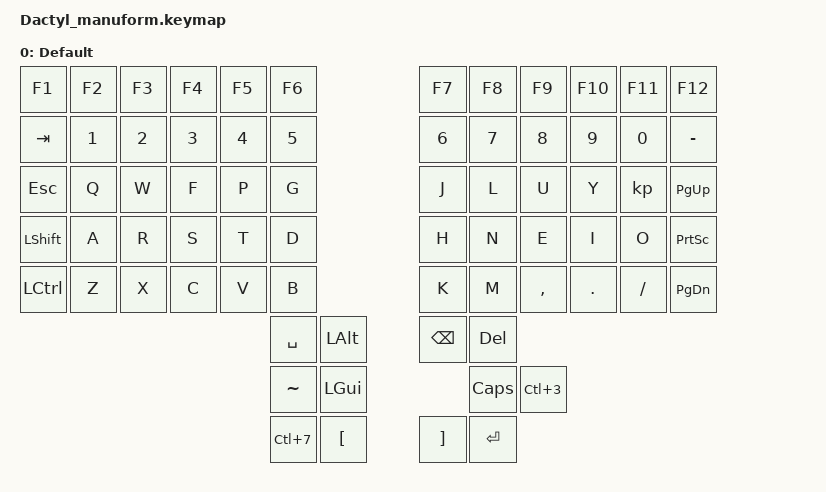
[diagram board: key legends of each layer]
#define DEFAULT 0
//#define LOWER   1
//#define RAISE   2
//#define ADJUST  3

#define HYPER(key) LS(LC(LA(LG(key))))
#define MEH(key)   LS(LC(LA(key)))

&kpkscan0 {
    debounce-press-ms = <30>;
    debounce-release-ms = <30>;
};

/ {
    keymap {
        compatible = "zmk,keymap";

        // Default layer. Modeled after the original Kinesis layout with a few tweaks.
        // Equals above tab = ESC
        // Backslash below minus = Equals
        // Swapped up and down arrows
        default_layer {
            display-name = "Default";
            bindings = <
        &kp F1  &kp F2  &kp F3  &kp F4  &kp F5  &kp F6                  &kp F7 &kp F8 &kp F9      &kp F10  &kp F11    &kp F12
        &kp TAB &kp N1  &kp N2  &kp N3  &kp N4  &kp N5                  &kp N6 &kp N7 &kp N8      &kp N9   &kp N0     &kp MINUS
        &kp ESC &kp Q   &kp W   &kp F   &kp P   &kp G                   &kp J  &kp L  &kp U       &kp Y    &kp        &kp PG_UP
        &kp LSHFT &kp A &kp R   &kp S   &kp T   &kp D                   &kp H  &kp N  &kp E       &kp I    &kp O      &kp PSCRN
        &kp LCTRL &kp Z &kp X   &kp C   &kp V   &kp B                   &kp K  &kp M  &kp COMMA   &kp DOT  &kp FSLH   &kp PG_DN
                                                &kp SPACE  &kp LALT &kp BSPC    &kp DEL
                                                &kp TILDE  &kp LGUI &kp CAPSLOCK     &kp LC(3)
                                                &kp LC(7)  &kp LBKT &kp RBKT    &kp ENTER

            >;
        };

    }
}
